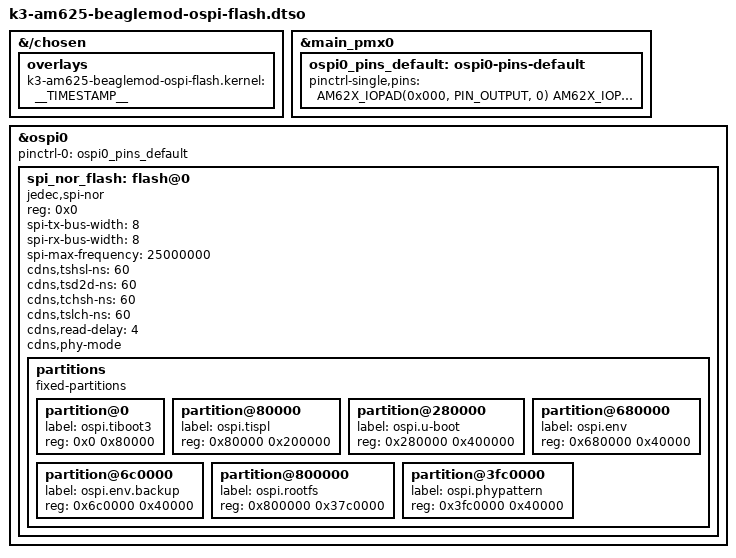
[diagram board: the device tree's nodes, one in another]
// SPDX-License-Identifier: GPL-2.0
/*
 * Copyright (C) 2022 Texas Instruments Incorporated - https://www.ti.com/
 */

/dts-v1/;
/plugin/;

#include "k3-pinctrl.h"

/*
 * Helper to show loaded overlays under: /proc/device-tree/chosen/overlays/
 */
&{/chosen} {
	overlays {
		k3-am625-beaglemod-ospi-flash.kernel = __TIMESTAMP__;
	};
};

&main_pmx0 {
        ospi0_pins_default: ospi0-pins-default {
                pinctrl-single,pins = <
                        AM62X_IOPAD(0x000, PIN_OUTPUT, 0) /* (H24) OSPI0_CLK */
                        AM62X_IOPAD(0x02c, PIN_OUTPUT, 0) /* (F23) OSPI0_CSn0 */
                        AM62X_IOPAD(0x00c, PIN_INPUT, 0) /* (E25) OSPI0_D0 */
                        AM62X_IOPAD(0x010, PIN_INPUT, 0) /* (G24) OSPI0_D1 */
                        AM62X_IOPAD(0x014, PIN_INPUT, 0) /* (F25) OSPI0_D2 */
                        AM62X_IOPAD(0x018, PIN_INPUT, 0) /* (F24) OSPI0_D3 */
                        AM62X_IOPAD(0x01c, PIN_INPUT, 0) /* (J23) OSPI0_D4 */
                        AM62X_IOPAD(0x020, PIN_INPUT, 0) /* (J25) OSPI0_D5 */
                        AM62X_IOPAD(0x024, PIN_INPUT, 0) /* (H25) OSPI0_D6 */
                        AM62X_IOPAD(0x028, PIN_INPUT, 0) /* (J22) OSPI0_D7 */
                        AM62X_IOPAD(0x008, PIN_INPUT, 0) /* (J24) OSPI0_DQS */
                >;
        };
};

&ospi0 {
	pinctrl-names = "default";
	pinctrl-0 = <&ospi0_pins_default>;
	status = "okay";
	#address-cells = <1>;
	#size-cells = <0>;

	spi_nor_flash: flash@0 {
		compatible = "jedec,spi-nor";
		reg = <0x0>;
		spi-tx-bus-width = <8>;
		spi-rx-bus-width = <8>;
		spi-max-frequency = <25000000>;
		cdns,tshsl-ns = <60>;
		cdns,tsd2d-ns = <60>;
		cdns,tchsh-ns = <60>;
		cdns,tslch-ns = <60>;
		cdns,read-delay = <4>;
		cdns,phy-mode;

		partitions {
			compatible = "fixed-partitions";
			#address-cells = <1>;
			#size-cells = <1>;

			partition@0 {
				label = "ospi.tiboot3";
				reg = <0x0 0x80000>;
			};

			partition@80000 {
				label = "ospi.tispl";
				reg = <0x80000 0x200000>;
			};

			partition@280000 {
				label = "ospi.u-boot";
				reg = <0x280000 0x400000>;
			};

			partition@680000 {
				label = "ospi.env";
				reg = <0x680000 0x40000>;
			};

			partition@6c0000 {
				label = "ospi.env.backup";
				reg = <0x6c0000 0x40000>;
			};

			partition@800000 {
				label = "ospi.rootfs";
				reg = <0x800000 0x37c0000>;
			};

			partition@3fc0000 {
				label = "ospi.phypattern";
				reg = <0x3fc0000 0x40000>;
			};
		};
	};
};
